# LAV_AT_E70ES1 register map
Vendor: Latticsemi.com; Series: LAV-AT; File version: 1.0
soc_golden_gsrd
Registers are 32-bit, read-write, reset 0x0 unless marked. A register's access mark holds for its fields unless they carry their own. Offsets are from the block's base; lines under a group give offsets from that group; [hi:lo] are bit positions; {n}, {i} and the like mark numbered series; 'fields as' and 'values as' point back to an identical list; <NAME> marks a mode.

## Memory map
0x00000000 sysmem0_inst size 0x20000
0x40000000 gpio0_inst size 0x400
0x40001000 tse_mac0_inst size 0x4000
0x40090000 uart0_inst size 0x400
0x40097000 mbconfig0_inst size 0x1000
0x40098000 sgdma0_inst size 0x1000
0x40300000 qspi0_inst size 0x1000
0x80000000 lpddr4_mc_contr0_inst size 0x40000000
0xF2000000 cpu0_inst size 0x100000

## gpio0_inst
Base 0x40000000
0x00 RD_DATA_REG ro — Read Data Register
  [7:0] rd_data — Read actual values of GPIO's
0x04 WR_DATA_REG — Write Data Register
  [7:0] wr_data — Write GPIO output register
0x08 SET_DATA_REG wo — Set Data Register
  [7:0] set_data — Set GPIO output register
0x0C CLEAR_DATA_REG wo — Clear Data Register
  [7:0] clear_data — Clear GPIO output register
0x10 DIRECTION_REG — Direction Register
  [7:0] direction_reg — GPIO Direction register
0x14 INT_TYPE_REG — Interrupt Type Register
  [7:0] int_type — Interrupt Type Cofiguration Register, 1-Edge, 0-Level
0x18 INT_METHOD_REG — Interrupt Method Register
  [7:0] int_method — Interrupt Method Register, if Interrupt Type is Edge` 1-Rising edge 0-faling edge, if Interrupt Type is Level` 1-High level, 0-Low level
0x1C INT_STATUS_REG — Interrupt Status Register
  [7:0] int_status — Interrupt Status Register, indicates interrupt status
0x20 INT_ENABLE_REG — Interrupt Enable Register
  [7:0] Int_enable — Interrupt Enable Register, enables appropriate channel interrupt
0x24 INT_SET_REG wo — Interrupt Set Register
  [7:0] int_set — Interrupt Set Register, user can generate interrupt by writing '1' to the corresponding bit of this register

## sgdma0_inst
Base 0x40098000
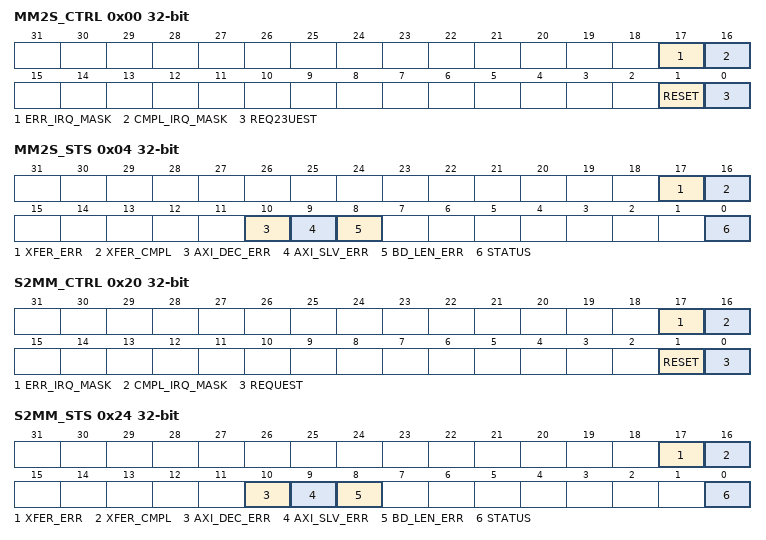
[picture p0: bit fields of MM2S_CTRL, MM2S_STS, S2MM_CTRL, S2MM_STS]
0x00 MM2S_CTRL — Memory Map to Streaming Control Register
  [17] ERR_IRQ_MASK — To mask out Interrupt event when Error detected.
  [16] CMPL_IRQ_MASK — To mask out Interrupt event upon transfer completion.
  [1] RESET wo — Soft reset to reset MM2S DMA core.
  [0] REQ23UEST ro — Request to start DMA operation.
0x04 MM2S_STS ro — Memory Map to Streaming Status Register
  [17] XFER_ERR — Current Transfer detected error.
  [16] XFER_CMPL — Current Transfer status.
  [10] AXI_DEC_ERR — AXI-MM Read RESP = DEC_ERR.
  [9] AXI_SLV_ERR — AXI-MM Read RESP = SLV_ERR
  [8] BD_LEN_ERR — Descriptor Buffer Length error.
  [0] STATUS — MM2S DMA operation status
0x08 MM2S_CURDESC — Memory Map to Streaming Current Descriptor Pointer.
  [31:0] MM2S_CURDESC — Address pointer to Current MM2S Descriptor.
0x20 S2MM_CTRL — Memory Map to Streaming Control Register
  [17] ERR_IRQ_MASK — To mask out Interrupt event when Error detected.
  [16] CMPL_IRQ_MASK — To mask out Interrupt event upon transfer completion.
  [1] RESET wo — Soft reset to reset S2MM DMA core.
  [0] REQUEST — Request to start DMA operation.
0x24 S2MM_STS ro — Memory Map to Streaming Status Register.
  [17] XFER_ERR — Current Transfer detected error.
  [16] XFER_CMPL — Current Transfer status.
  [10] AXI_DEC_ERR — AXI-MM Read RESP = DEC_ER.
  [9] AXI_SLV_ERR — AXI-MM Read RESP = SLV_ERR.
  [8] BD_LEN_ERR — Descriptor�s Buffer Length error.
  [0] STATUS — S2MM DMA operation status.
0x28 S2MM_CURDESC — Memory Map to Streaming Current Descriptor Pointer
  [31:0] S2MM_CURDESC — Address pointer to Current S2MM Descriptor.

## uart0_inst
Base 0x40090000
0x00 THR wo — Transmitter Holding Register is the interface to the Transmitter Buffer/FIFO (XMIT FIFO).
  [7:0] XMIT_FIFO — Write access to this field pushes data to XMIT FIFO
0x00 RBR ro — Receive Buffer Register is the interface to the Receiver Buffer/FIFO (RCVR FIFO).
  [7:0] RCVR_FIFO — Read access to this field pops data from RCVR FIFO
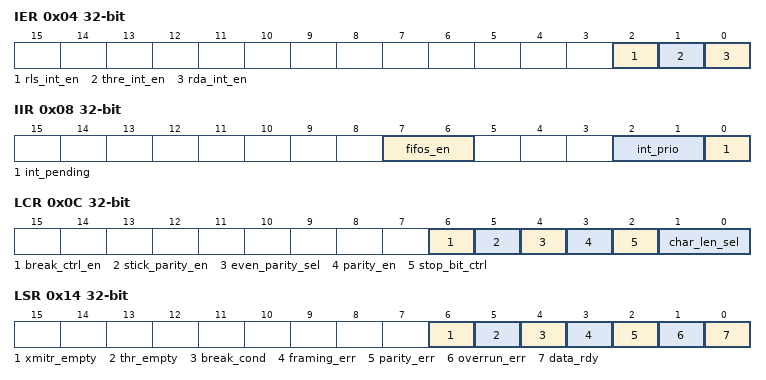
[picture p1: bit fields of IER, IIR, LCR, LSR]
0x04 IER — Interrupt Enable Register enables the four types of UART interrupts.
  [2] rls_int_en — Receiver Line Status Interrupt Enable. 0-> Interrupt is disabled. 1-> Interrupt is enabled.
  [1] thre_int_en — Transmitter Holding Register Empty Interrupt Enable. 0-> Interrupt is disabled. 1-> Interrupt is enabled.
  [0] rda_int_en — Received Data Available Interrupt Enable. 0-> Interrupt is disabled. 1-> Interrupt is enabled.
0x08 IIR ro — Interrupt Identification Register determines the asserted interrupt based on priority.
  [7:6] fifos_en — FIFO mode - Fixed to logic 2'b11. Non-FIFO mode - fixed to 2'b00.
  [2:1] int_prio — 2'b11 -> Receiver Line Status Interrupt. 2'b10 -> Received Data Available Interrupt. 2'b01 -> Transmitter Holding Register Empty Interrupt. 2'b00 -> MODEM Status Interrupt.
  [0] int_pending — 0 -> Interrupt is pending according to int_prio and timeout_int. 1 -> No pending interrupt.
0x0C LCR — Line Control Register configures character length, number stop bits and parity bit.
  [6] break_ctrl_en — Break Control Enable. 0 -> Break control is disabled. 1 -> Break control is enabled.
  [5] stick_parity_en — Stick Parity Enable. 0 -> Stick parity is disabled. 1 -> Stick parity is enabled.
  [4] even_parity_sel — Even Parity Select. 0 -> Odd parity. 1 -> Even Parity.
  [3] parity_en — Parity Enable. 0-> Parity generation and checking is disabled. 1-> Parity generation and checking is enabled.
  [2] stop_bit_ctrl — 0 -> One stop bit is generated in the transmitted data. 1 -> Two stop bits are generated.
  [1:0] char_len_sel — 2'b00 -> 5 bits. 2'b01 -> 6 bits. 2'b10 -> 7 bits. 2'b11 -> 8 bits.
0x14 LSR ro — Line Status Register
  [6] xmitr_empty — Transmitter Empty bit asserts when both XMIT FIFO and Transmitter Shift Register are empty.
  [5] thr_empty — THR Empty bit asserts when XMIT FIFO is empty.
  [4] break_cond — Break condition indicator asserts when rxd_i is held low for longer than full RX time.
  [3] framing_err — Framing Error Indicator asserts when received data does not have a valid stop bit.
  [2] parity_err — Parity Error Indicator asserts when parity error occurs.
  [1] overrun_err — Overrun Error Indicator asserts when RCVR FIFO is full and the next character has been fully received.
  [0] data_rdy — Data Ready Indicator asserts when RCVR FIFO has data.
0x20 DLAB_LSB — Divisor Latch Register LSB
  [7:0] divisor_lsb — The lower byte of the Divisor Latch Register.
0x24 DLAB_MSB — Divisor Latch Register MSB
  [7:0] divisor_msb — The upper byte of the Divisor Latch Register.
